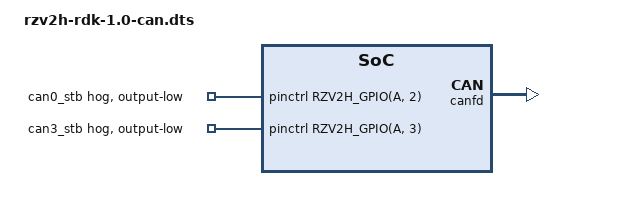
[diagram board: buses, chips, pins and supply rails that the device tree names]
// SPDX-License-Identifier: GPL-2.0+
/*
 * Copyright (C) 2025 Renesas Electronics Corporation
 */

/dts-v1/;
/plugin/;

#include <dt-bindings/pinctrl/rzv2h-pinctrl.h>
#include <dt-bindings/gpio/gpio.h>

&pinctrl {
    can0_pins: can0 {
        pinmux = <RZV2H_PORT_PINMUX(8, 0, 5)>, 	/* CTX0 */
                <RZV2H_PORT_PINMUX(8, 1, 5)>; 	/* CRX0 */
    };

    can0-stb-hog {
        gpio-hog;
        gpios = <RZV2H_GPIO(A, 2) GPIO_ACTIVE_HIGH>;
        output-low;
        line-name = "can0_stb";
    };

    can3_pins: can3 {
        pinmux = <RZV2H_PORT_PINMUX(8, 6, 5)>, 	/* CTX3 */
                <RZV2H_PORT_PINMUX(8, 7, 5)>; 	/* CRX3 */
    };

    can3-stb-hog {
        gpio-hog;
        gpios = <RZV2H_GPIO(A, 3) GPIO_ACTIVE_HIGH>;
        output-low;
        line-name = "can3_stb";
    };
};

&canfd {
    pinctrl-0 = <&can0_pins &can3_pins>;
    pinctrl-names = "default";
    status = "okay";

    channel0 {
        status = "okay";
    };

    channel3 {
        status = "okay";
    };
};
